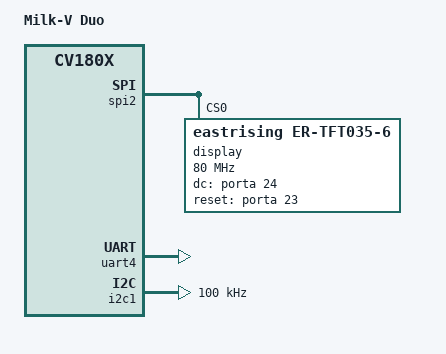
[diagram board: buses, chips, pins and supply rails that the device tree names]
/dts-v1/;
#include "cv180x_base_riscv.dtsi"
#include "cv180x_asic_qfn.dtsi"
#include "cv180x_asic_sd.dtsi"
#include "cv180x_default_memmap.dtsi"

&mipi_rx{
	snsr-reset = <&portc 8 GPIO_ACTIVE_LOW>, <&portc 8 GPIO_ACTIVE_LOW>, <&portc 8 GPIO_ACTIVE_LOW>;
};

&spi2 {
  status = "okay";
  /delete-node/ spidev@0;
  display@0{
  compatible = "eastrising,er-tft035-6"; //匹配驱动名称，使用st7789的话修改为sitronix,st7789v_240x320
      
  reg = < 0 >;
  status = "okay";
  spi-max-frequency = < 80000000 >;
  spi-cpol;
  spi-cpha;
  dc-gpios = < &porta 24 GPIO_ACTIVE_HIGH >;  //GPIOA_24做DC脚
  reset-gpios = < &porta 23 GPIO_ACTIVE_HIGH >; //GPIOA_23做Reset脚
  rotation = < 180 >;
  };
};

&uart4 {
	status = "okay";
};

&i2c1 {
       status = "okay";
       clock-frequency = <100000>;
};

/ {
	model = "Milk-V Duo";
};

